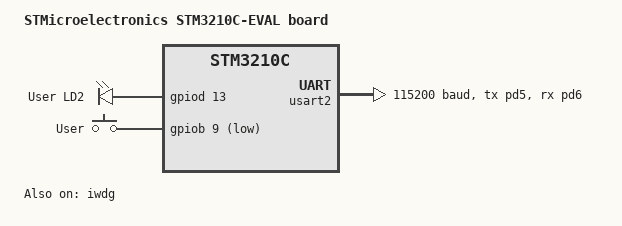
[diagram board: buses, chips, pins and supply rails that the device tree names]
/*
 * Copyright (c) 2017 Linaro Limited
 *
 * SPDX-License-Identifier: Apache-2.0
 */

/dts-v1/;
#include <st/f1/stm32f107Xc.dtsi>
#include <st/f1/stm32f107v(b-c)tx-pinctrl.dtsi>

/ {
	model = "STMicroelectronics STM3210C-EVAL board";
	compatible = "st,stm3210c-eval";

	chosen {
		zephyr,console = &usart2;
		zephyr,shell-uart = &usart2;
		zephyr,sram = &sram0;
		zephyr,flash = &flash0;
	};

	leds {
		compatible = "gpio-leds";
		green_led_2: led_2 {
			gpios = <&gpiod 13 GPIO_ACTIVE_HIGH>;
			label = "User LD2";
		};
	};

	gpio_keys {
		compatible = "gpio-keys";
		user_button: button {
			label = "User";
			gpios = <&gpiob 9 GPIO_ACTIVE_LOW>;
		};
	};

	aliases {
		led0 = &green_led_2;
		sw0 = &user_button;
	};
};

&usart2 {
	pinctrl-0 = <&usart2_tx_pd5 &usart2_rx_pd6>;
	current-speed = <115200>;
	status = "okay";
};

&iwdg {
	status = "okay";
};
